AUTOSAR XML (schema 4-2-1)
package /VehicleProject
  system System
package /NM
  nm config NmConfig: can-nm-cluster-coupling=coupled-cluster=CAN00_CAN
    can nm cluster CAN00_CAN: communication-cluster=CAN00, nm-channel-id=0, nm-cbv-position=1, nm-network-timeout=1, nm-repeat-message-time=0.4, nm-user-data-length=6, nm-wait-bus-sleep-time=0.75
      can nm node MyECU: controller=CT_CAN00, nm-if-ecu=MyECU_CAN, nm-node-id=0, rx-nm-pdu=msg_NM_RearECU_oCAN00, tx-nm-pdu=msg_NM_MyECU_oCAN00, nm-msg-cycle-offset=0, nm-range-config={lower-can-id=1536, upper-can-id=1599}
      can nm node RearECU: nm-if-ecu=RearECU_CAN, nm-node-id=1, rx-nm-pdu=msg_NM_MyECU_oCAN00, tx-nm-pdu=msg_NM_RearECU_oCAN00, nm-msg-cycle-offset=0, nm-range-config={lower-can-id=1536, upper-can-id=1599}
    nm-if-ecus:
      nm ecu MyECU_CAN: ecu-instance=MyECU, nm-node-id-enabled=true, nm-user-data-enabled=true
      nm ecu RearECU_CAN: nm-node-id-enabled=true, nm-user-data-enabled=true
package /Cluster
  can cluster CAN00: protocol-name=CAN
    can physical channel CHNL: comm-connectors=CN_CAN00
      frame msg_MyECU_Lamp_oCAN00: id 0x511, from MyECU, frame-length=8, can-addressing-mode=STANDARD
        pdu msg_MyECU_Lamp_oCAN00: length=8, minimum-delay=0, transmission-mode-false-timing=cyclic-timing={time-offset=0, time-period=0.1}, transmission-mode-true-timing=cyclic-timing={time-offset=0, time-period=0.1}, unused-bit-pattern=0
          signal sig_LampCnt_omsg_MyECU_Lamp_oCAN00: start 7, 8 bit, big-endian, init-value=0, base-type=uint8, compu-method=CM_sig_LampCnt, transfer-property=PENDING
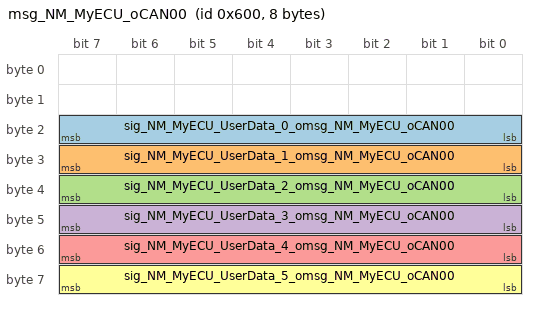
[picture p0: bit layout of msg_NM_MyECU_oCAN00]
      frame msg_NM_MyECU_oCAN00: id 0x600, from MyECU, frame-length=8, can-addressing-mode=STANDARD
        nm pdu msg_NM_MyECU_oCAN00: length=8, unused-bit-pattern=0
          signal sig_NM_MyECU_UserData_0_omsg_NM_MyECU_oCAN00: start 16, 8 bit, little-endian, init-value=0, base-type=uint8, compu-method=CM_sig_NM_MyECU_UserData_0, transfer-property=PENDING
          signal sig_NM_MyECU_UserData_1_omsg_NM_MyECU_oCAN00: start 24, 8 bit, little-endian, init-value=0, base-type=uint8, compu-method=CM_sig_NM_MyECU_UserData_1, transfer-property=PENDING
          signal sig_NM_MyECU_UserData_2_omsg_NM_MyECU_oCAN00: start 32, 8 bit, little-endian, init-value=0, base-type=uint8, compu-method=CM_sig_NM_MyECU_UserData_2, transfer-property=PENDING
          signal sig_NM_MyECU_UserData_3_omsg_NM_MyECU_oCAN00: start 40, 8 bit, little-endian, init-value=0, base-type=uint8, compu-method=CM_sig_NM_MyECU_UserData_3, transfer-property=PENDING
          signal sig_NM_MyECU_UserData_4_omsg_NM_MyECU_oCAN00: start 48, 8 bit, little-endian, init-value=0, base-type=uint8, compu-method=CM_sig_NM_MyECU_UserData_4, transfer-property=PENDING
          signal sig_NM_MyECU_UserData_5_omsg_NM_MyECU_oCAN00: start 56, 8 bit, little-endian, init-value=0, base-type=uint8, compu-method=CM_sig_NM_MyECU_UserData_5, transfer-property=PENDING
      frame msg_NM_RearECU_oCAN00: id 0x601, to MyECU, frame-length=8, can-addressing-mode=STANDARD
        nm pdu msg_NM_RearECU_oCAN00: length=8, unused-bit-pattern=0
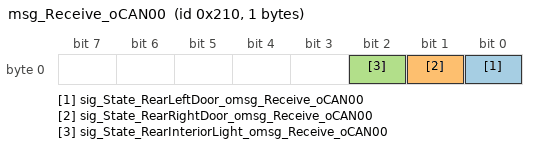
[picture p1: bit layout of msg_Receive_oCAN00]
      frame msg_Receive_oCAN00: id 0x210, to MyECU, frame-length=1, can-addressing-mode=STANDARD
        pdu msg_Receive_oCAN00: length=1, minimum-delay=0, transmission-mode-false-timing=cyclic-timing={time-offset=0, time-period=0.1}, transmission-mode-true-timing=cyclic-timing={time-offset=0, time-period=0.1}, unused-bit-pattern=0
          signal sig_State_RearLeftDoor_omsg_Receive_oCAN00: start 0, 1 bit, little-endian, init-value=0, base-type=boolean, compu-method=CM_sig_State_RearLeftDoor, transfer-property=PENDING, to MyECU
          signal sig_State_RearRightDoor_omsg_Receive_oCAN00: start 1, 1 bit, little-endian, init-value=0, base-type=boolean, compu-method=CM_sig_State_RearRightDoor, transfer-property=PENDING, to MyECU
          signal sig_State_RearInteriorLight_omsg_Receive_oCAN00: start 2, 1 bit, little-endian, init-value=0, base-type=boolean, compu-method=CM_sig_State_RearInteriorLight, transfer-property=PENDING, to MyECU
      frame msg_Transmit_oCAN00: id 0x200, from MyECU, frame-length=1, can-addressing-mode=STANDARD
        pdu msg_Transmit_oCAN00: length=1, minimum-delay=0, transmission-mode-false-timing=cyclic-timing={time-offset=0, time-period=0.1}, transmission-mode-true-timing=cyclic-timing={time-offset=0, time-period=0.1}, unused-bit-pattern=0
          signal sig_RearInteriorLight_omsg_Transmit_oCAN00: start 0, 1 bit, little-endian, init-value=0, base-type=boolean, compu-method=CM_sig_RearInteriorLight, transfer-property=PENDING
package /ECU
  ecu instance MyECU: associated-com-i-pdu-group=[MyECU_oCAN00_Rx, MyECU_oCAN00_Tx]
    can communication controller CT_CAN00
    can communication connector CN_CAN00: comm-controller=CT_CAN00
package /IPDUGroup
  i signal i pdu group MyECU_oCAN00_Rx: communication-direction=IN, i-signal-i-pdus=msg_Receive_oCAN00
  i signal i pdu group MyECU_oCAN00_Tx: communication-direction=OUT, i-signal-i-pdus=[msg_MyECU_Lamp_oCAN00, msg_Transmit_oCAN00]
